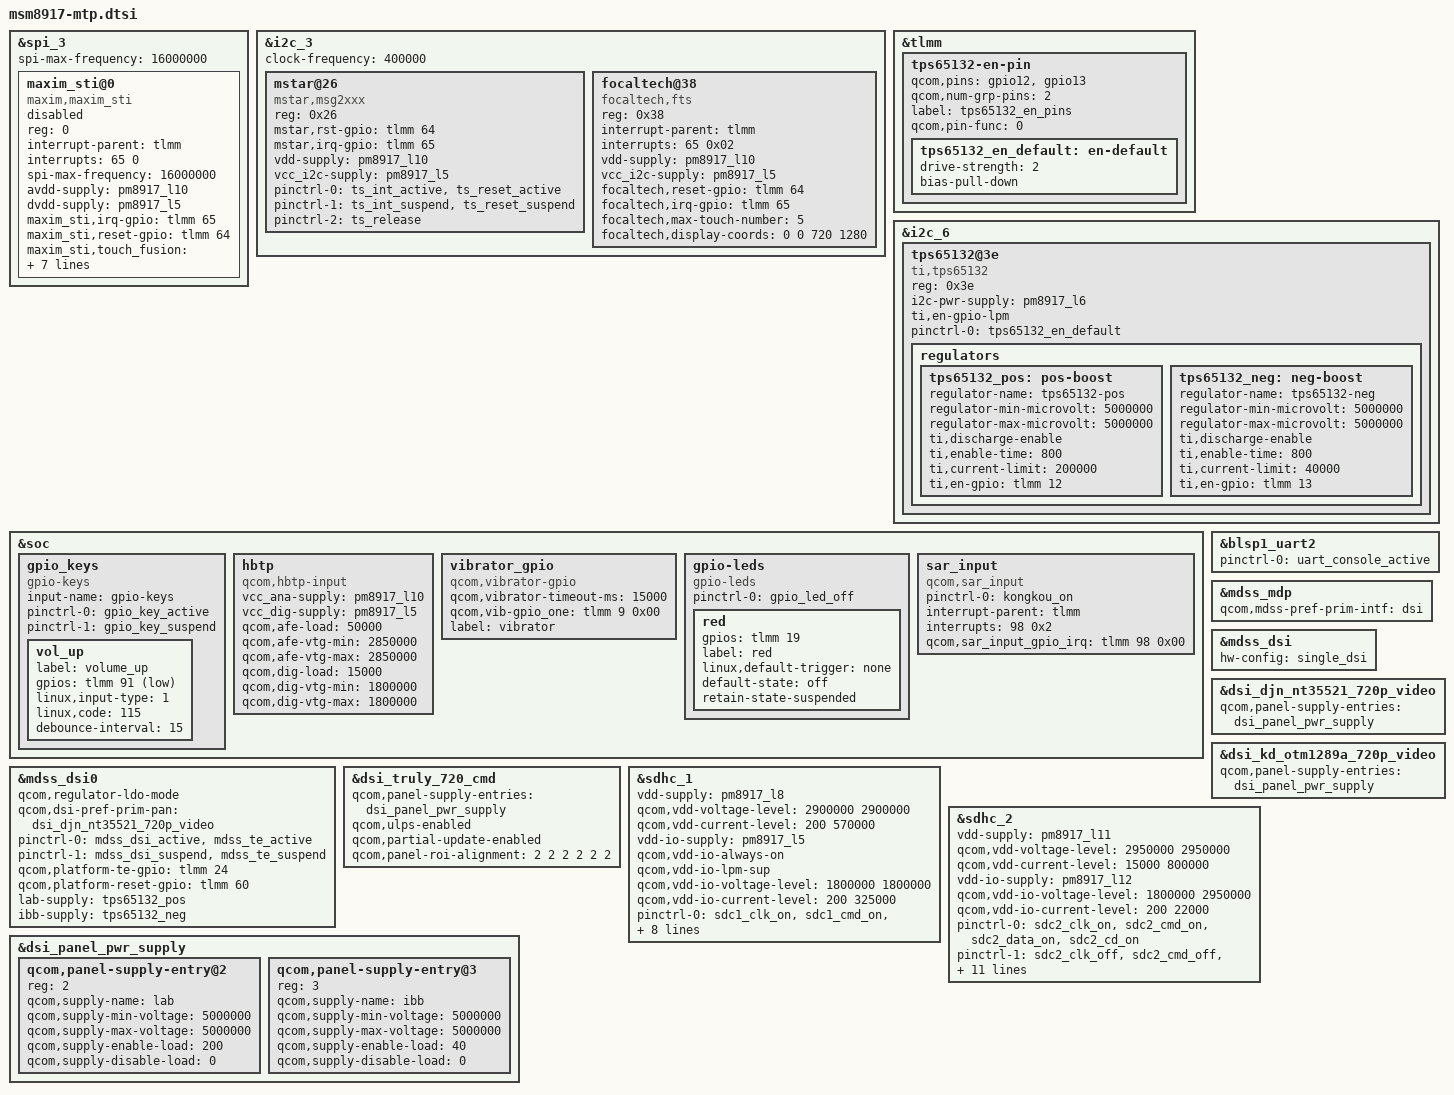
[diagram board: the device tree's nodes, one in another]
/*
 * Copyright (c) 2015-2016, The Linux Foundation. All rights reserved.
 *
 * This program is free software; you can redistribute it and/or modify
 * it under the terms of the GNU General Public License version 2 and
 * only version 2 as published by the Free Software Foundation.
 *
 * This program is distributed in the hope that it will be useful,
 * but WITHOUT ANY WARRANTY; without even the implied warranty of
 * MERCHANTABILITY or FITNESS FOR A PARTICULAR PURPOSE.  See the
 * GNU General Public License for more details.
 */

#include "msm8917-pinctrl.dtsi"
#include "msm8917-camera-sensor-mtp.dtsi"

&spi_3 { /* BLSP1 QUP3 */
	spi-max-frequency = <16000000>;
	maxim_sti@0 {
		status = "disabled";
		compatible = "maxim,maxim_sti";
		reg = <0>;
		interrupt-parent = <&tlmm>;
		interrupts = <65 0>;
		spi-max-frequency = <16000000>;
		avdd-supply = <&pm8917_l10>;
		dvdd-supply = <&pm8917_l5>;
		maxim_sti,irq-gpio = <&tlmm 65 0x00>;
		maxim_sti,reset-gpio = <&tlmm 64 0x00>;
		maxim_sti,touch_fusion = "/vendor/bin/touch_fusion";
		maxim_sti,config_file = "/etc/firmware/qtc800s.cfg";
		maxim_sti,fw_name = "qtc800s.bin";
		pinctrl-names = "pmx_ts_active","pmx_ts_suspend",
			"pmx_ts_release";
		pinctrl-0 = <&ts_int_active &ts_reset_active>;
		pinctrl-1 = <&ts_int_suspend &ts_reset_suspend>;
		pinctrl-2 = <&ts_release>;
	};
};

&i2c_3 {
    status = "ok";
    clock-frequency = <400000>;
    mstar@26{                                                                                                                                                                            
        compatible = "mstar,msg2xxx";
        reg = <0x26>;
        //interrupt-parent = <&msm_gpio>;
        //interrupts = <13 0x2008>;
        mstar,rst-gpio = <&tlmm 64 0x0>;
        mstar,irq-gpio =  <&tlmm 65 0x0>;
        vdd-supply =  <&pm8917_l10>;
        vcc_i2c-supply =  <&pm8917_l5>;
        pinctrl-names = "pmx_ts_active","pmx_ts_suspend","pmx_ts_release";
        pinctrl-0 = <&ts_int_active &ts_reset_active>;
        pinctrl-1 = <&ts_int_suspend &ts_reset_suspend>;
        pinctrl-2 = <&ts_release>;
    };  
	
focaltech@38{ 
	compatible = "focaltech,fts";	
	reg = <0x38>;  					
	interrupt-parent = <&tlmm>;				
	interrupts = <65 0x02>;
	vdd-supply =  <&pm8917_l10>;
	vcc_i2c-supply =  <&pm8917_l5>;
	focaltech,reset-gpio = <&tlmm 64 0x0>; 
	focaltech,irq-gpio = <&tlmm 65 0x0>; 	
	focaltech,max-touch-number = <5>;			
	focaltech,display-coords =  <0 0 720 1280>;	 
#if 0
	focaltech,have-key;
	focaltech,key-number = <3>;	
	focaltech,keys = <139 102 158>; 	
	focaltech,key-y-coord = <2000>; 
	focaltech,key-x-coords = <200 600 800>;
#endif
};



};

&tlmm {
        tps65132-en-pin {
                qcom,pins = "gpio12", "gpio13";
                qcom,num-grp-pins = <2>;
                label = "tps65132_en_pins";
                qcom,pin-func = <0>;

                tps65132_en_default: en-default {
                        drive-strength = <2>;
                        bias-pull-down;
                };
        };
};
&i2c_6{ /* BLSP2 QUP2 */
        tps65132@3e {
                compatible = "ti,tps65132";
                reg = <0x3e>;
                i2c-pwr-supply = <&pm8917_l6>;
                ti,en-gpio-lpm;
                pinctrl-names = "default";
                pinctrl-0 = <&tps65132_en_default>;

                regulators {
                        tps65132_pos: pos-boost {
                                regulator-name = "tps65132-pos";
                                regulator-min-microvolt = <5000000>;
                                regulator-max-microvolt = <5000000>;
                                ti,discharge-enable;
                                ti,enable-time = <800>;
                                ti,current-limit = <200000>;
                                ti,en-gpio = <&tlmm 12 0>;
                        };

                        tps65132_neg: neg-boost {
                                regulator-name = "tps65132-neg";
                                regulator-min-microvolt = <5000000>;
                                regulator-max-microvolt = <5000000>;
                                ti,discharge-enable;
                                ti,enable-time = <800>;
                                ti,current-limit = <40000>;
                                ti,en-gpio = <&tlmm 13 0>;
                        };
                };
        };
};

&soc {
	gpio_keys {
		compatible = "gpio-keys";
		input-name = "gpio-keys";
		pinctrl-names = "tlmm_gpio_key_active","tlmm_gpio_key_suspend";
		pinctrl-0 = <&gpio_key_active>;
		pinctrl-1 = <&gpio_key_suspend>;

		vol_up {
			label = "volume_up";
			gpios = <&tlmm 91 0x1>;
			linux,input-type = <1>;
			linux,code = <115>;
			debounce-interval = <15>;
		};
	};

	hbtp {
		compatible = "qcom,hbtp-input";
		vcc_ana-supply = <&pm8917_l10>;
		vcc_dig-supply = <&pm8917_l5>;
		qcom,afe-load = <50000>;
		qcom,afe-vtg-min = <2850000>;
		qcom,afe-vtg-max = <2850000>;
		qcom,dig-load = <15000>;
		qcom,dig-vtg-min = <1800000>;
		qcom,dig-vtg-max = <1800000>;
	};

	vibrator_gpio {
		compatible = "qcom,vibrator-gpio";
		qcom,vibrator-timeout-ms = <15000>;
		qcom,vib-gpio_one = <&tlmm 9 0x00>;
		label = "vibrator";
	};

	gpio-leds {
		compatible = "gpio-leds";
		status = "okay";
		pinctrl-names = "default";
		pinctrl-0 = <&gpio_led_off>;

		red {
			 gpios = <&tlmm 19 0>;
			 label = "red";
			 linux,default-trigger = "none";
			 default-state = "off";
			 retain-state-suspended;
		};
	};

	sar_input {
		compatible = "qcom,sar_input";
		pinctrl-names = "default";
		pinctrl-0 = <&kongkou_on>;
		interrupt-parent = <&tlmm>;
		interrupts = <98 0x2>;
		qcom,sar_input_gpio_irq = <&tlmm 98 0x00>;
	};
};
/*
&flash_led {
	compatible = "qcom,qpnp-flash-led";
	reg = <0xd300 0x100>;
	pinctrl-names = "flash_led_enable","flash_led_disable";
	pinctrl-0 = <&rear_flash_led_enable>;
	pinctrl-1 = <&rear_flash_led_disable>;
	qcom,follow-otst2-rb-disabled;
};

&wled {
	qcom,cons-sync-write-delay-us = <1000>;
};

&pmi_haptic{
	qcom,actuator-type = "lra";
	qcom,wave-play-rate-us = <4165>;
	qcom,lra-auto-res-mode="qwd";
	qcom,lra-high-z="opt1";
	qcom,lra-res-cal-period = <0>;
};
*/
&blsp1_uart2 {
	status = "ok";
	pinctrl-names = "default";
	pinctrl-0 = <&uart_console_active>;
};

#include "msm8937-mdss-panels.dtsi"

&mdss_mdp {
	qcom,mdss-pref-prim-intf = "dsi";
};

&mdss_dsi {
	hw-config = "single_dsi";
};

&mdss_dsi0 {
	qcom,regulator-ldo-mode;
	qcom,dsi-pref-prim-pan = <&dsi_djn_nt35521_720p_video>;
	pinctrl-names = "mdss_default", "mdss_sleep";
	pinctrl-0 = <&mdss_dsi_active &mdss_te_active>;
	pinctrl-1 = <&mdss_dsi_suspend &mdss_te_suspend>;

	qcom,platform-te-gpio = <&tlmm 24 0>;
	qcom,platform-reset-gpio = <&tlmm 60 0>;
	lab-supply = <&tps65132_pos>;
	ibb-supply = <&tps65132_neg>;
	//qcom,platform-bklight-en-gpio = <&tlmm 98 0>;
};

&dsi_djn_nt35521_720p_video {
	qcom,panel-supply-entries = <&dsi_panel_pwr_supply>;
	//qcom,mdss-dsi-pan-enable-dynamic-fps;
	//qcom,mdss-dsi-pan-fps-update = "dfps_immediate_porch_mode_vfp";
};

&dsi_kd_otm1289a_720p_video {
        qcom,panel-supply-entries = <&dsi_panel_pwr_supply>;
};

&dsi_truly_720_cmd {
	qcom,panel-supply-entries = <&dsi_panel_pwr_supply>;
	qcom,ulps-enabled;
	qcom,partial-update-enabled;
	qcom,panel-roi-alignment = <2 2 2 2 2 2>;
};

&sdhc_1 {
	/* device core power supply */
	vdd-supply = <&pm8917_l8>;
	qcom,vdd-voltage-level = <2900000 2900000>;
	qcom,vdd-current-level = <200 570000>;

	/* device communication power supply */
	vdd-io-supply = <&pm8917_l5>;
	qcom,vdd-io-always-on;
	qcom,vdd-io-lpm-sup;
	qcom,vdd-io-voltage-level = <1800000 1800000>;
	qcom,vdd-io-current-level = <200 325000>;

	pinctrl-names = "active", "sleep";
	pinctrl-0 = <&sdc1_clk_on &sdc1_cmd_on &sdc1_data_on &sdc1_rclk_on>;
	pinctrl-1 = <&sdc1_clk_off &sdc1_cmd_off &sdc1_data_off &sdc1_rclk_off>;

	qcom,clk-rates = <400000 20000000 25000000 50000000 100000000 192000000
								384000000>;
	qcom,nonremovable;
	qcom,bus-speed-mode = "HS400_1p8v", "HS200_1p8v", "DDR_1p8v";

	status = "ok";
};

&sdhc_2 {
	/* device core power supply */
	vdd-supply = <&pm8917_l11>;
	qcom,vdd-voltage-level = <2950000 2950000>;
	qcom,vdd-current-level = <15000 800000>;

	/* device communication power supply */
	vdd-io-supply = <&pm8917_l12>;
	qcom,vdd-io-voltage-level = <1800000 2950000>;
	qcom,vdd-io-current-level = <200 22000>;

	pinctrl-names = "active", "sleep";
	pinctrl-0 = <&sdc2_clk_on &sdc2_cmd_on &sdc2_data_on &sdc2_cd_on>;
	pinctrl-1 = <&sdc2_clk_off &sdc2_cmd_off &sdc2_data_off>;

	#address-cells = <0>;
	interrupt-parent = <&sdhc_2>;
	interrupts = <0 1 2>;
	#interrupt-cells = <1>;
	interrupt-map-mask = <0xffffffff>;
	interrupt-map = <0 &intc 0 125 0
		1 &intc 0 221 0
		2 &tlmm 67 0>;
	interrupt-names = "hc_irq", "pwr_irq", "status_irq";
	cd-gpios = <&tlmm 67 0x1>;

	qcom,clk-rates = <400000 20000000 25000000 50000000 100000000
								200000000>;
	qcom,bus-speed-mode = "SDR12", "SDR25", "SDR50", "DDR50", "SDR104";

	status = "ok";
};

&dsi_panel_pwr_supply {
	qcom,panel-supply-entry@2 {
		reg = <2>;
		qcom,supply-name = "lab";
		qcom,supply-min-voltage = <5000000>;
		qcom,supply-max-voltage = <5000000>;
		qcom,supply-enable-load = <200>;
		qcom,supply-disable-load = <0>;
	};

	qcom,panel-supply-entry@3 {
		reg = <3>;
		qcom,supply-name = "ibb";
		qcom,supply-min-voltage = <5000000>;
		qcom,supply-max-voltage = <5000000>;
		qcom,supply-enable-load = <40>;
		qcom,supply-disable-load = <0>;
	};
};
